# MSS_CTRL_MSS_CTRL_50D00000h register map
Vendor: Texas Instruments
Registers are 32-bit, read-write, reset values left out (the file's numbers can be read two ways) unless marked. A register's access mark holds for its fields unless they carry their own. Offsets are as the file gives them; [hi:lo] are bit positions; {n}, {i} and the like mark numbered series.

## MSS_CTRL (part 3 of 6)
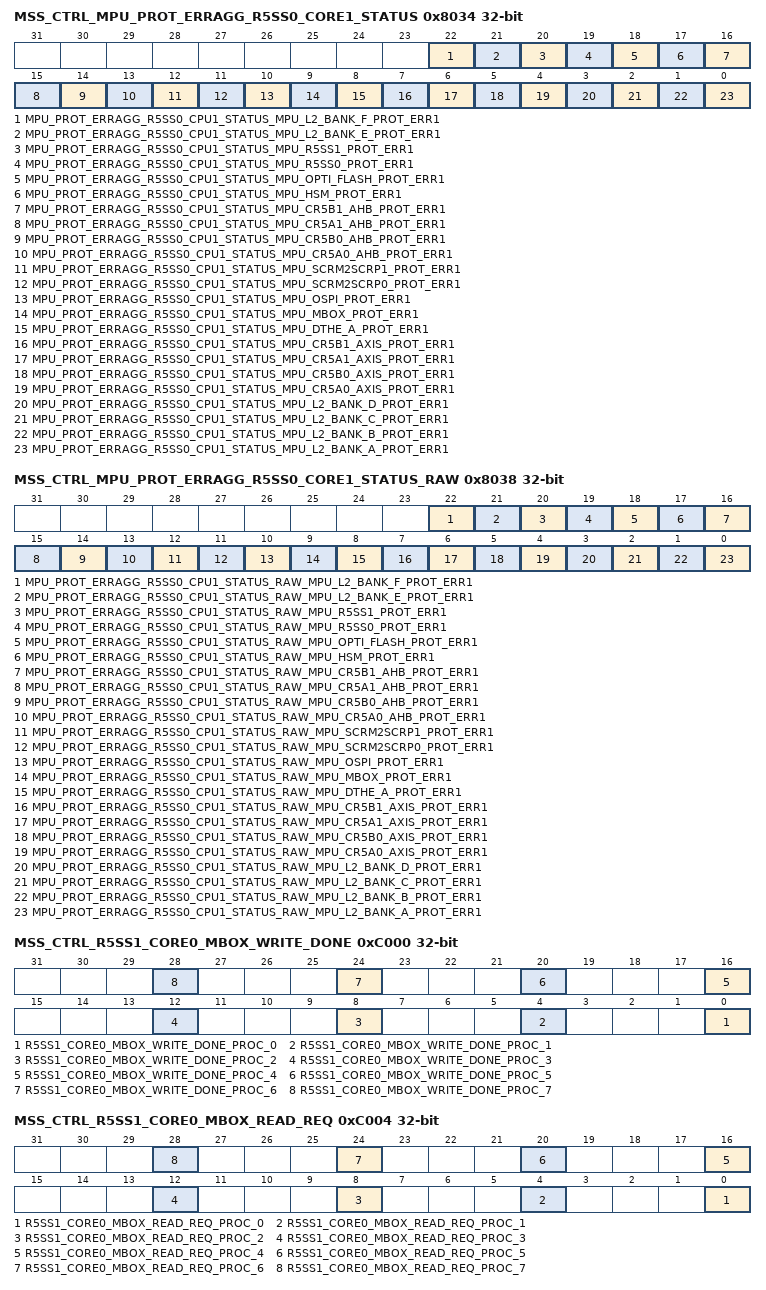
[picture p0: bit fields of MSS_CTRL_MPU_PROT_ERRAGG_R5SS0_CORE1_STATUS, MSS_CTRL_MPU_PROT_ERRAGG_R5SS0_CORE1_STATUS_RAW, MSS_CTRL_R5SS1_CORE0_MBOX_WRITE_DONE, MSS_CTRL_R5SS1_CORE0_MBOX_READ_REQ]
0x8034 MSS_CTRL_MPU_PROT_ERRAGG_R5SS0_CORE1_STATUS
  [22] MPU_PROT_ERRAGG_R5SS0_CPU1_STATUS_MPU_L2_BANK_F_PROT_ERR1 — Status of Error from MPU_PROT_INTR. Set only if Interupt is unmasked in MPU_PROT_INTR_ERRAGG_MASKWrie 0x1 to clear this Error.
  [21] MPU_PROT_ERRAGG_R5SS0_CPU1_STATUS_MPU_L2_BANK_E_PROT_ERR1 — Status of Error from MPU_PROT_INTR. Set only if Interupt is unmasked in MPU_PROT_INTR_ERRAGG_MASKWrie 0x1 to clear this Error.
  [20] MPU_PROT_ERRAGG_R5SS0_CPU1_STATUS_MPU_R5SS1_PROT_ERR1 — Status of Error from MPU_PROT_INTR. Set only if Interupt is unmasked in MPU_PROT_INTR_ERRAGG_MASKWrie 0x1 to clear this Error.
  [19] MPU_PROT_ERRAGG_R5SS0_CPU1_STATUS_MPU_R5SS0_PROT_ERR1 — Status of Error from MPU_PROT_INTR. Set only if Interupt is unmasked in MPU_PROT_INTR_ERRAGG_MASKWrie 0x1 to clear this Error.
  [18] MPU_PROT_ERRAGG_R5SS0_CPU1_STATUS_MPU_OPTI_FLASH_PROT_ERR1 — Status of Error from MPU_PROT_INTR. Set only if Interupt is unmasked in MPU_PROT_INTR_ERRAGG_MASKWrie 0x1 to clear this Error.
  [17] MPU_PROT_ERRAGG_R5SS0_CPU1_STATUS_MPU_HSM_PROT_ERR1 — Status of Error from MPU_PROT_INTR. Set only if Interupt is unmasked in MPU_PROT_INTR_ERRAGG_MASKWrie 0x1 to clear this Error.
  [16] MPU_PROT_ERRAGG_R5SS0_CPU1_STATUS_MPU_CR5B1_AHB_PROT_ERR1 — Status of Error from MPU_PROT_INTR. Set only if Interupt is unmasked in MPU_PROT_INTR_ERRAGG_MASKWrie 0x1 to clear this Error.
  [15] MPU_PROT_ERRAGG_R5SS0_CPU1_STATUS_MPU_CR5A1_AHB_PROT_ERR1 — Status of Error from MPU_PROT_INTR. Set only if Interupt is unmasked in MPU_PROT_INTR_ERRAGG_MASKWrie 0x1 to clear this Error.
  [14] MPU_PROT_ERRAGG_R5SS0_CPU1_STATUS_MPU_CR5B0_AHB_PROT_ERR1 — Status of Error from MPU_PROT_INTR. Set only if Interupt is unmasked in MPU_PROT_INTR_ERRAGG_MASKWrie 0x1 to clear this Error.
  [13] MPU_PROT_ERRAGG_R5SS0_CPU1_STATUS_MPU_CR5A0_AHB_PROT_ERR1 — Status of Error from MPU_PROT_INTR. Set only if Interupt is unmasked in MPU_PROT_INTR_ERRAGG_MASKWrie 0x1 to clear this Error.
  [12] MPU_PROT_ERRAGG_R5SS0_CPU1_STATUS_MPU_SCRM2SCRP1_PROT_ERR1 — Status of Error from MPU_PROT_INTR. Set only if Interupt is unmasked in MPU_PROT_INTR_ERRAGG_MASKWrie 0x1 to clear this Error.
  [11] MPU_PROT_ERRAGG_R5SS0_CPU1_STATUS_MPU_SCRM2SCRP0_PROT_ERR1 — Status of Error from MPU_PROT_INTR. Set only if Interupt is unmasked in MPU_PROT_INTR_ERRAGG_MASKWrie 0x1 to clear this Error.
  [10] MPU_PROT_ERRAGG_R5SS0_CPU1_STATUS_MPU_OSPI_PROT_ERR1 — Status of Error from MPU_PROT_INTR. Set only if Interupt is unmasked in MPU_PROT_INTR_ERRAGG_MASKWrie 0x1 to clear this Error.
  [9] MPU_PROT_ERRAGG_R5SS0_CPU1_STATUS_MPU_MBOX_PROT_ERR1 — Status of Error from MPU_PROT_INTR. Set only if Interupt is unmasked in MPU_PROT_INTR_ERRAGG_MASKWrie 0x1 to clear this Error.
  [8] MPU_PROT_ERRAGG_R5SS0_CPU1_STATUS_MPU_DTHE_A_PROT_ERR1 — Status of Error from MPU_PROT_INTR. Set only if Interupt is unmasked in MPU_PROT_INTR_ERRAGG_MASKWrie 0x1 to clear this Error.
  [7] MPU_PROT_ERRAGG_R5SS0_CPU1_STATUS_MPU_CR5B1_AXIS_PROT_ERR1 — Status of Error from MPU_PROT_INTR. Set only if Interupt is unmasked in MPU_PROT_INTR_ERRAGG_MASKWrie 0x1 to clear this Error.
  [6] MPU_PROT_ERRAGG_R5SS0_CPU1_STATUS_MPU_CR5A1_AXIS_PROT_ERR1 — Status of Error from MPU_PROT_INTR. Set only if Interupt is unmasked in MPU_PROT_INTR_ERRAGG_MASKWrie 0x1 to clear this Error.
  [5] MPU_PROT_ERRAGG_R5SS0_CPU1_STATUS_MPU_CR5B0_AXIS_PROT_ERR1 — Status of Error from MPU_PROT_INTR. Set only if Interupt is unmasked in MPU_PROT_INTR_ERRAGG_MASKWrie 0x1 to clear this Error.
  [4] MPU_PROT_ERRAGG_R5SS0_CPU1_STATUS_MPU_CR5A0_AXIS_PROT_ERR1 — Status of Error from MPU_PROT_INTR. Set only if Interupt is unmasked in MPU_PROT_INTR_ERRAGG_MASKWrie 0x1 to clear this Error.
  [3] MPU_PROT_ERRAGG_R5SS0_CPU1_STATUS_MPU_L2_BANK_D_PROT_ERR1 — Status of Error from MPU_PROT_INTR. Set only if Interupt is unmasked in MPU_PROT_INTR_ERRAGG_MASKWrie 0x1 to clear this Error.
  [2] MPU_PROT_ERRAGG_R5SS0_CPU1_STATUS_MPU_L2_BANK_C_PROT_ERR1 — Status of Error from MPU_PROT_INTR. Set only if Interupt is unmasked in MPU_PROT_INTR_ERRAGG_MASKWrie 0x1 to clear this Error.
  [1] MPU_PROT_ERRAGG_R5SS0_CPU1_STATUS_MPU_L2_BANK_B_PROT_ERR1 — Status of Error from MPU_PROT_INTR. Set only if Interupt is unmasked in MPU_PROT_INTR_ERRAGG_MASKWrie 0x1 to clear this Error.
  [0] MPU_PROT_ERRAGG_R5SS0_CPU1_STATUS_MPU_L2_BANK_A_PROT_ERR1 — Status of Error from MPU_PROT_INTR. Set only if Interupt is unmasked in MPU_PROT_INTR_ERRAGG_MASKWrie 0x1 to clear this Error.
0x8038 MSS_CTRL_MPU_PROT_ERRAGG_R5SS0_CORE1_STATUS_RAW
  [22] MPU_PROT_ERRAGG_R5SS0_CPU1_STATUS_RAW_MPU_L2_BANK_F_PROT_ERR1 — Raw Status of Error from MPU_PROT_INTR. Set irrespective if the Interupt is masked or unmasked in MPU_PROT_INTR_ERRAGG_MASK
  [21] MPU_PROT_ERRAGG_R5SS0_CPU1_STATUS_RAW_MPU_L2_BANK_E_PROT_ERR1 — Raw Status of Error from MPU_PROT_INTR. Set irrespective if the Interupt is masked or unmasked in MPU_PROT_INTR_ERRAGG_MASK
  [20] MPU_PROT_ERRAGG_R5SS0_CPU1_STATUS_RAW_MPU_R5SS1_PROT_ERR1 — Raw Status of Error from MPU_PROT_INTR. Set irrespective if the Interupt is masked or unmasked in MPU_PROT_INTR_ERRAGG_MASK
  [19] MPU_PROT_ERRAGG_R5SS0_CPU1_STATUS_RAW_MPU_R5SS0_PROT_ERR1 — Raw Status of Error from MPU_PROT_INTR. Set irrespective if the Interupt is masked or unmasked in MPU_PROT_INTR_ERRAGG_MASK
  [18] MPU_PROT_ERRAGG_R5SS0_CPU1_STATUS_RAW_MPU_OPTI_FLASH_PROT_ERR1 — Raw Status of Error from MPU_PROT_INTR. Set irrespective if the Interupt is masked or unmasked in MPU_PROT_INTR_ERRAGG_MASK
  [17] MPU_PROT_ERRAGG_R5SS0_CPU1_STATUS_RAW_MPU_HSM_PROT_ERR1 — Raw Status of Error from MPU_PROT_INTR. Set irrespective if the Interupt is masked or unmasked in MPU_PROT_INTR_ERRAGG_MASK
  [16] MPU_PROT_ERRAGG_R5SS0_CPU1_STATUS_RAW_MPU_CR5B1_AHB_PROT_ERR1 — Raw Status of Error from MPU_PROT_INTR. Set irrespective if the Interupt is masked or unmasked in MPU_PROT_INTR_ERRAGG_MASK
  [15] MPU_PROT_ERRAGG_R5SS0_CPU1_STATUS_RAW_MPU_CR5A1_AHB_PROT_ERR1 — Raw Status of Error from MPU_PROT_INTR. Set irrespective if the Interupt is masked or unmasked in MPU_PROT_INTR_ERRAGG_MASK
  [14] MPU_PROT_ERRAGG_R5SS0_CPU1_STATUS_RAW_MPU_CR5B0_AHB_PROT_ERR1 — Raw Status of Error from MPU_PROT_INTR. Set irrespective if the Interupt is masked or unmasked in MPU_PROT_INTR_ERRAGG_MASK
  [13] MPU_PROT_ERRAGG_R5SS0_CPU1_STATUS_RAW_MPU_CR5A0_AHB_PROT_ERR1 — Raw Status of Error from MPU_PROT_INTR. Set irrespective if the Interupt is masked or unmasked in MPU_PROT_INTR_ERRAGG_MASK
  [12] MPU_PROT_ERRAGG_R5SS0_CPU1_STATUS_RAW_MPU_SCRM2SCRP1_PROT_ERR1 — Raw Status of Error from MPU_PROT_INTR. Set irrespective if the Interupt is masked or unmasked in MPU_PROT_INTR_ERRAGG_MASK
  [11] MPU_PROT_ERRAGG_R5SS0_CPU1_STATUS_RAW_MPU_SCRM2SCRP0_PROT_ERR1 — Raw Status of Error from MPU_PROT_INTR. Set irrespective if the Interupt is masked or unmasked in MPU_PROT_INTR_ERRAGG_MASK
  [10] MPU_PROT_ERRAGG_R5SS0_CPU1_STATUS_RAW_MPU_OSPI_PROT_ERR1 — Raw Status of Error from MPU_PROT_INTR. Set irrespective if the Interupt is masked or unmasked in MPU_PROT_INTR_ERRAGG_MASK
  [9] MPU_PROT_ERRAGG_R5SS0_CPU1_STATUS_RAW_MPU_MBOX_PROT_ERR1 — Raw Status of Error from MPU_PROT_INTR. Set irrespective if the Interupt is masked or unmasked in MPU_PROT_INTR_ERRAGG_MASK
  [8] MPU_PROT_ERRAGG_R5SS0_CPU1_STATUS_RAW_MPU_DTHE_A_PROT_ERR1 — Raw Status of Error from MPU_PROT_INTR. Set irrespective if the Interupt is masked or unmasked in MPU_PROT_INTR_ERRAGG_MASK
  [7] MPU_PROT_ERRAGG_R5SS0_CPU1_STATUS_RAW_MPU_CR5B1_AXIS_PROT_ERR1 — Raw Status of Error from MPU_PROT_INTR. Set irrespective if the Interupt is masked or unmasked in MPU_PROT_INTR_ERRAGG_MASK
  [6] MPU_PROT_ERRAGG_R5SS0_CPU1_STATUS_RAW_MPU_CR5A1_AXIS_PROT_ERR1 — Raw Status of Error from MPU_PROT_INTR. Set irrespective if the Interupt is masked or unmasked in MPU_PROT_INTR_ERRAGG_MASK
  [5] MPU_PROT_ERRAGG_R5SS0_CPU1_STATUS_RAW_MPU_CR5B0_AXIS_PROT_ERR1 — Raw Status of Error from MPU_PROT_INTR. Set irrespective if the Interupt is masked or unmasked in MPU_PROT_INTR_ERRAGG_MASK
  [4] MPU_PROT_ERRAGG_R5SS0_CPU1_STATUS_RAW_MPU_CR5A0_AXIS_PROT_ERR1 — Raw Status of Error from MPU_PROT_INTR. Set irrespective if the Interupt is masked or unmasked in MPU_PROT_INTR_ERRAGG_MASK
  [3] MPU_PROT_ERRAGG_R5SS0_CPU1_STATUS_RAW_MPU_L2_BANK_D_PROT_ERR1 — Raw Status of Error from MPU_PROT_INTR. Set irrespective if the Interupt is masked or unmasked in MPU_PROT_INTR_ERRAGG_MASK
  [2] MPU_PROT_ERRAGG_R5SS0_CPU1_STATUS_RAW_MPU_L2_BANK_C_PROT_ERR1 — Raw Status of Error from MPU_PROT_INTR. Set irrespective if the Interupt is masked or unmasked in MPU_PROT_INTR_ERRAGG_MASK
  [1] MPU_PROT_ERRAGG_R5SS0_CPU1_STATUS_RAW_MPU_L2_BANK_B_PROT_ERR1 — Raw Status of Error from MPU_PROT_INTR. Set irrespective if the Interupt is masked or unmasked in MPU_PROT_INTR_ERRAGG_MASK
  [0] MPU_PROT_ERRAGG_R5SS0_CPU1_STATUS_RAW_MPU_L2_BANK_A_PROT_ERR1 — Raw Status of Error from MPU_PROT_INTR. Set irrespective if the Interupt is masked or unmasked in MPU_PROT_INTR_ERRAGG_MASK
0xC000 MSS_CTRL_R5SS1_CORE0_MBOX_WRITE_DONE
  [4n] R5SS1_CORE0_MBOX_WRITE_DONE_PROC_{n} (n=0..7) — Write pulse bit field:This register should be written once finishing Writing into the mailbox memory of processor {n}
0xC004 MSS_CTRL_R5SS1_CORE0_MBOX_READ_REQ
  [4n] R5SS1_CORE0_MBOX_READ_REQ_PROC_{n} (n=0..7) — This is request from processor {n} to mss_cr5a. Requesting it to read from mailbox.
0xC008 MSS_CTRL_R5SS1_CORE0_MBOX_READ_DONE_ACK
  [7:0] R5SS1_CORE0_MBOX_READ_DONE_ACK_PROC — Write pulse bit field:For bits 0 to7:Wrting1'b1 : Generates pulse interrupt to corresponding proc from MSS_CR5
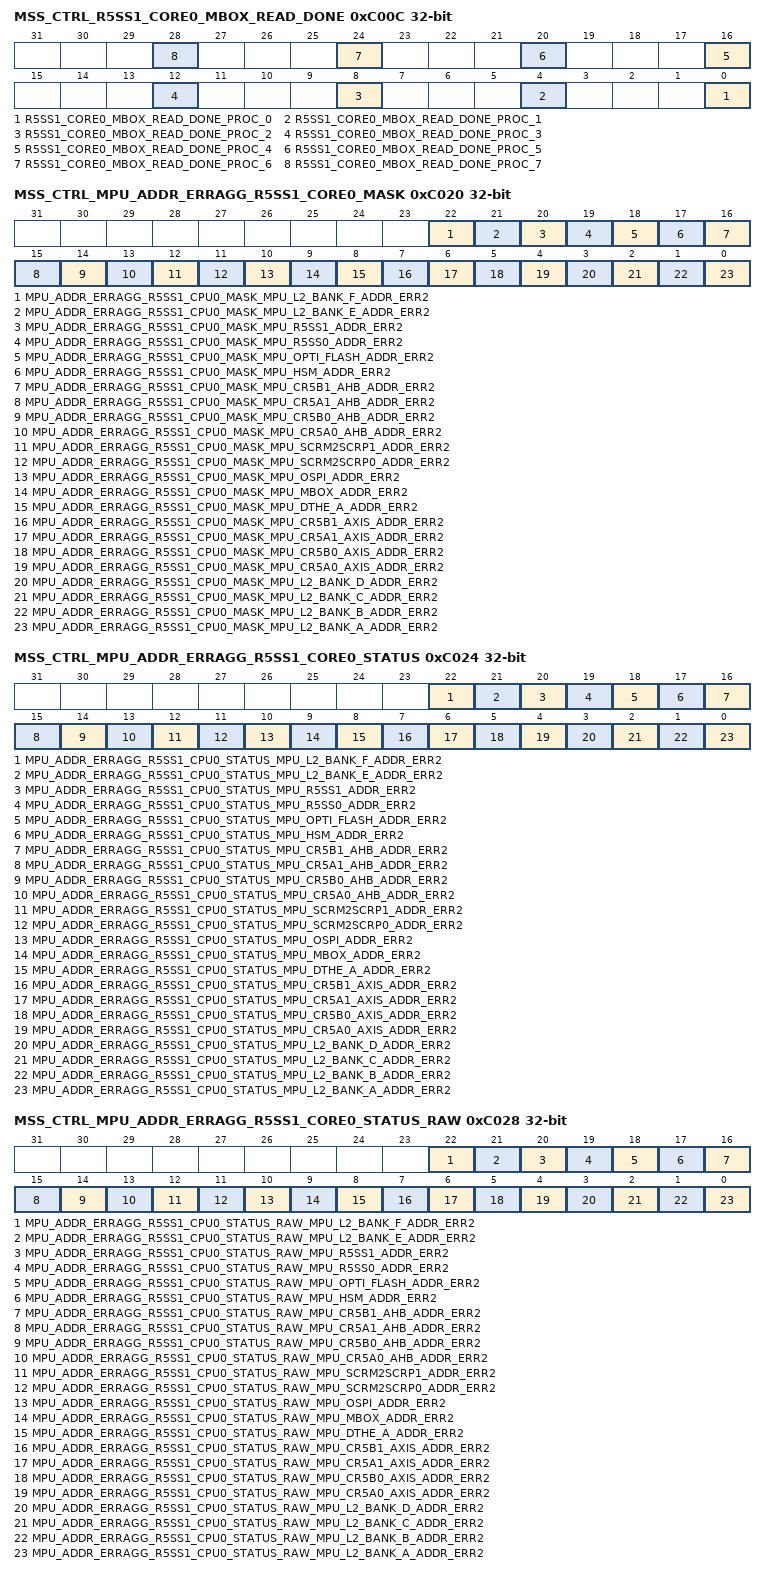
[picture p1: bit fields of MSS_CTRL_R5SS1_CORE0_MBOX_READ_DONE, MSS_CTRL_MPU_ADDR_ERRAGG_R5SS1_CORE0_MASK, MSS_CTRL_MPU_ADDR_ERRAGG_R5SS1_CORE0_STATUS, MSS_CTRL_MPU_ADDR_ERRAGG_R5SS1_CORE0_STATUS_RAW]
0xC00C MSS_CTRL_R5SS1_CORE0_MBOX_READ_DONE
  [4n] R5SS1_CORE0_MBOX_READ_DONE_PROC_{n} (n=0..7) — This register should be written once finishing Reading from proc{n}'s mailbox written by CR5A
0xC010 MSS_CTRL_R5SS1_CORE0_SW_INT
  [0] R5SS1_CORE0_SW_INT_PULSE — Write_pulse bit field:Writing 1'b1 to each bit will trigger MSS_SW_INT respectively to CR5A/B.
0xC020 MSS_CTRL_MPU_ADDR_ERRAGG_R5SS1_CORE0_MASK
  [22] MPU_ADDR_ERRAGG_R5SS1_CPU0_MASK_MPU_L2_BANK_F_ADDR_ERR2 — Mask Error from MPU_ADDR_INTR to aggregated Error MPU_ADDR_INTR_ERRAGG1'b1 : Error is Masked1'b0 : Error is Unmasked
  [21] MPU_ADDR_ERRAGG_R5SS1_CPU0_MASK_MPU_L2_BANK_E_ADDR_ERR2 — Mask Error from MPU_ADDR_INTR to aggregated Error MPU_ADDR_INTR_ERRAGG1'b1 : Error is Masked1'b0 : Error is Unmasked
  [20] MPU_ADDR_ERRAGG_R5SS1_CPU0_MASK_MPU_R5SS1_ADDR_ERR2 — Mask Error from MPU_ADDR_INTR to aggregated Error MPU_ADDR_INTR_ERRAGG1'b1 : Error is Masked1'b0 : Error is Unmasked
  [19] MPU_ADDR_ERRAGG_R5SS1_CPU0_MASK_MPU_R5SS0_ADDR_ERR2 — Mask Error from MPU_ADDR_INTR to aggregated Error MPU_ADDR_INTR_ERRAGG1'b1 : Error is Masked1'b0 : Error is Unmasked
  [18] MPU_ADDR_ERRAGG_R5SS1_CPU0_MASK_MPU_OPTI_FLASH_ADDR_ERR2 — Mask Error from MPU_ADDR_INTR to aggregated Error MPU_ADDR_INTR_ERRAGG1'b1 : Error is Masked1'b0 : Error is Unmasked
  [17] MPU_ADDR_ERRAGG_R5SS1_CPU0_MASK_MPU_HSM_ADDR_ERR2 — Mask Error from MPU_ADDR_INTR to aggregated Error MPU_ADDR_INTR_ERRAGG1'b1 : Error is Masked1'b0 : Error is Unmasked
  [16] MPU_ADDR_ERRAGG_R5SS1_CPU0_MASK_MPU_CR5B1_AHB_ADDR_ERR2 — Mask Error from MPU_ADDR_INTR to aggregated Error MPU_ADDR_INTR_ERRAGG1'b1 : Error is Masked1'b0 : Error is Unmasked
  [15] MPU_ADDR_ERRAGG_R5SS1_CPU0_MASK_MPU_CR5A1_AHB_ADDR_ERR2 — Mask Error from MPU_ADDR_INTR to aggregated Error MPU_ADDR_INTR_ERRAGG1'b1 : Error is Masked1'b0 : Error is Unmasked
  [14] MPU_ADDR_ERRAGG_R5SS1_CPU0_MASK_MPU_CR5B0_AHB_ADDR_ERR2 — Mask Error from MPU_ADDR_INTR to aggregated Error MPU_ADDR_INTR_ERRAGG1'b1 : Error is Masked1'b0 : Error is Unmasked
  [13] MPU_ADDR_ERRAGG_R5SS1_CPU0_MASK_MPU_CR5A0_AHB_ADDR_ERR2 — Mask Error from MPU_ADDR_INTR to aggregated Error MPU_ADDR_INTR_ERRAGG1'b1 : Error is Masked1'b0 : Error is Unmasked
  [12] MPU_ADDR_ERRAGG_R5SS1_CPU0_MASK_MPU_SCRM2SCRP1_ADDR_ERR2 — Mask Error from MPU_ADDR_INTR to aggregated Error MPU_ADDR_INTR_ERRAGG1'b1 : Error is Masked1'b0 : Error is Unmasked
  [11] MPU_ADDR_ERRAGG_R5SS1_CPU0_MASK_MPU_SCRM2SCRP0_ADDR_ERR2 — Mask Error from MPU_ADDR_INTR to aggregated Error MPU_ADDR_INTR_ERRAGG1'b1 : Error is Masked1'b0 : Error is Unmasked
  [10] MPU_ADDR_ERRAGG_R5SS1_CPU0_MASK_MPU_OSPI_ADDR_ERR2 — Mask Error from MPU_ADDR_INTR to aggregated Error MPU_ADDR_INTR_ERRAGG1'b1 : Error is Masked1'b0 : Error is Unmasked
  [9] MPU_ADDR_ERRAGG_R5SS1_CPU0_MASK_MPU_MBOX_ADDR_ERR2 — Mask Error from MPU_ADDR_INTR to aggregated Error MPU_ADDR_INTR_ERRAGG1'b1 : Error is Masked1'b0 : Error is Unmasked
  [8] MPU_ADDR_ERRAGG_R5SS1_CPU0_MASK_MPU_DTHE_A_ADDR_ERR2 — Mask Error from MPU_ADDR_INTR to aggregated Error MPU_ADDR_INTR_ERRAGG1'b1 : Error is Masked1'b0 : Error is Unmasked
  [7] MPU_ADDR_ERRAGG_R5SS1_CPU0_MASK_MPU_CR5B1_AXIS_ADDR_ERR2 — Mask Error from MPU_ADDR_INTR to aggregated Error MPU_ADDR_INTR_ERRAGG1'b1 : Error is Masked1'b0 : Error is Unmasked
  [6] MPU_ADDR_ERRAGG_R5SS1_CPU0_MASK_MPU_CR5A1_AXIS_ADDR_ERR2 — Mask Error from MPU_ADDR_INTR to aggregated Error MPU_ADDR_INTR_ERRAGG1'b1 : Error is Masked1'b0 : Error is Unmasked
  [5] MPU_ADDR_ERRAGG_R5SS1_CPU0_MASK_MPU_CR5B0_AXIS_ADDR_ERR2 — Mask Error from MPU_ADDR_INTR to aggregated Error MPU_ADDR_INTR_ERRAGG1'b1 : Error is Masked1'b0 : Error is Unmasked
  [4] MPU_ADDR_ERRAGG_R5SS1_CPU0_MASK_MPU_CR5A0_AXIS_ADDR_ERR2 — Mask Error from MPU_ADDR_INTR to aggregated Error MPU_ADDR_INTR_ERRAGG1'b1 : Error is Masked1'b0 : Error is Unmasked
  [3] MPU_ADDR_ERRAGG_R5SS1_CPU0_MASK_MPU_L2_BANK_D_ADDR_ERR2 — Mask Error from MPU_ADDR_INTR to aggregated Error MPU_ADDR_INTR_ERRAGG1'b1 : Error is Masked1'b0 : Error is Unmasked
  [2] MPU_ADDR_ERRAGG_R5SS1_CPU0_MASK_MPU_L2_BANK_C_ADDR_ERR2 — Mask Error from MPU_ADDR_INTR to aggregated Error MPU_ADDR_INTR_ERRAGG1'b1 : Error is Masked1'b0 : Error is Unmasked
  [1] MPU_ADDR_ERRAGG_R5SS1_CPU0_MASK_MPU_L2_BANK_B_ADDR_ERR2 — Mask Error from MPU_ADDR_INTR to aggregated Error MPU_ADDR_INTR_ERRAGG1'b1 : Error is Masked1'b0 : Error is Unmasked
  [0] MPU_ADDR_ERRAGG_R5SS1_CPU0_MASK_MPU_L2_BANK_A_ADDR_ERR2 — Mask Error from MPU_ADDR_INTR to aggregated Error MPU_ADDR_INTR_ERRAGG1'b1 : Error is Masked1'b0 : Error is Unmasked
0xC024 MSS_CTRL_MPU_ADDR_ERRAGG_R5SS1_CORE0_STATUS
  [22] MPU_ADDR_ERRAGG_R5SS1_CPU0_STATUS_MPU_L2_BANK_F_ADDR_ERR2 — Status of Error from MPU_ADDR_INTR. Set only if Interupt is unmasked in MPU_ADDR_INTR_ERRAGG_MASKWrie 0x1 to clear this Error.
  [21] MPU_ADDR_ERRAGG_R5SS1_CPU0_STATUS_MPU_L2_BANK_E_ADDR_ERR2 — Status of Error from MPU_ADDR_INTR. Set only if Interupt is unmasked in MPU_ADDR_INTR_ERRAGG_MASKWrie 0x1 to clear this Error.
  [20] MPU_ADDR_ERRAGG_R5SS1_CPU0_STATUS_MPU_R5SS1_ADDR_ERR2 — Status of Error from MPU_ADDR_INTR. Set only if Interupt is unmasked in MPU_ADDR_INTR_ERRAGG_MASKWrie 0x1 to clear this Error.
  [19] MPU_ADDR_ERRAGG_R5SS1_CPU0_STATUS_MPU_R5SS0_ADDR_ERR2 — Status of Error from MPU_ADDR_INTR. Set only if Interupt is unmasked in MPU_ADDR_INTR_ERRAGG_MASKWrie 0x1 to clear this Error.
  [18] MPU_ADDR_ERRAGG_R5SS1_CPU0_STATUS_MPU_OPTI_FLASH_ADDR_ERR2 — Status of Error from MPU_ADDR_INTR. Set only if Interupt is unmasked in MPU_ADDR_INTR_ERRAGG_MASKWrie 0x1 to clear this Error.
  [17] MPU_ADDR_ERRAGG_R5SS1_CPU0_STATUS_MPU_HSM_ADDR_ERR2 — Status of Error from MPU_ADDR_INTR. Set only if Interupt is unmasked in MPU_ADDR_INTR_ERRAGG_MASKWrie 0x1 to clear this Error.
  [16] MPU_ADDR_ERRAGG_R5SS1_CPU0_STATUS_MPU_CR5B1_AHB_ADDR_ERR2 — Status of Error from MPU_ADDR_INTR. Set only if Interupt is unmasked in MPU_ADDR_INTR_ERRAGG_MASKWrie 0x1 to clear this Error.
  [15] MPU_ADDR_ERRAGG_R5SS1_CPU0_STATUS_MPU_CR5A1_AHB_ADDR_ERR2 — Status of Error from MPU_ADDR_INTR. Set only if Interupt is unmasked in MPU_ADDR_INTR_ERRAGG_MASKWrie 0x1 to clear this Error.
  [14] MPU_ADDR_ERRAGG_R5SS1_CPU0_STATUS_MPU_CR5B0_AHB_ADDR_ERR2 — Status of Error from MPU_ADDR_INTR. Set only if Interupt is unmasked in MPU_ADDR_INTR_ERRAGG_MASKWrie 0x1 to clear this Error.
  [13] MPU_ADDR_ERRAGG_R5SS1_CPU0_STATUS_MPU_CR5A0_AHB_ADDR_ERR2 — Status of Error from MPU_ADDR_INTR. Set only if Interupt is unmasked in MPU_ADDR_INTR_ERRAGG_MASKWrie 0x1 to clear this Error.
  [12] MPU_ADDR_ERRAGG_R5SS1_CPU0_STATUS_MPU_SCRM2SCRP1_ADDR_ERR2 — Status of Error from MPU_ADDR_INTR. Set only if Interupt is unmasked in MPU_ADDR_INTR_ERRAGG_MASKWrie 0x1 to clear this Error.
  [11] MPU_ADDR_ERRAGG_R5SS1_CPU0_STATUS_MPU_SCRM2SCRP0_ADDR_ERR2 — Status of Error from MPU_ADDR_INTR. Set only if Interupt is unmasked in MPU_ADDR_INTR_ERRAGG_MASKWrie 0x1 to clear this Error.
  [10] MPU_ADDR_ERRAGG_R5SS1_CPU0_STATUS_MPU_OSPI_ADDR_ERR2 — Status of Error from MPU_ADDR_INTR. Set only if Interupt is unmasked in MPU_ADDR_INTR_ERRAGG_MASKWrie 0x1 to clear this Error.
  [9] MPU_ADDR_ERRAGG_R5SS1_CPU0_STATUS_MPU_MBOX_ADDR_ERR2 — Status of Error from MPU_ADDR_INTR. Set only if Interupt is unmasked in MPU_ADDR_INTR_ERRAGG_MASKWrie 0x1 to clear this Error.
  [8] MPU_ADDR_ERRAGG_R5SS1_CPU0_STATUS_MPU_DTHE_A_ADDR_ERR2 — Status of Error from MPU_ADDR_INTR. Set only if Interupt is unmasked in MPU_ADDR_INTR_ERRAGG_MASKWrie 0x1 to clear this Error.
  [7] MPU_ADDR_ERRAGG_R5SS1_CPU0_STATUS_MPU_CR5B1_AXIS_ADDR_ERR2 — Status of Error from MPU_ADDR_INTR. Set only if Interupt is unmasked in MPU_ADDR_INTR_ERRAGG_MASKWrie 0x1 to clear this Error.
  [6] MPU_ADDR_ERRAGG_R5SS1_CPU0_STATUS_MPU_CR5A1_AXIS_ADDR_ERR2 — Status of Error from MPU_ADDR_INTR. Set only if Interupt is unmasked in MPU_ADDR_INTR_ERRAGG_MASKWrie 0x1 to clear this Error.
  [5] MPU_ADDR_ERRAGG_R5SS1_CPU0_STATUS_MPU_CR5B0_AXIS_ADDR_ERR2 — Status of Error from MPU_ADDR_INTR. Set only if Interupt is unmasked in MPU_ADDR_INTR_ERRAGG_MASKWrie 0x1 to clear this Error.
  [4] MPU_ADDR_ERRAGG_R5SS1_CPU0_STATUS_MPU_CR5A0_AXIS_ADDR_ERR2 — Status of Error from MPU_ADDR_INTR. Set only if Interupt is unmasked in MPU_ADDR_INTR_ERRAGG_MASKWrie 0x1 to clear this Error.
  [3] MPU_ADDR_ERRAGG_R5SS1_CPU0_STATUS_MPU_L2_BANK_D_ADDR_ERR2 — Status of Error from MPU_ADDR_INTR. Set only if Interupt is unmasked in MPU_ADDR_INTR_ERRAGG_MASKWrie 0x1 to clear this Error.
  [2] MPU_ADDR_ERRAGG_R5SS1_CPU0_STATUS_MPU_L2_BANK_C_ADDR_ERR2 — Status of Error from MPU_ADDR_INTR. Set only if Interupt is unmasked in MPU_ADDR_INTR_ERRAGG_MASKWrie 0x1 to clear this Error.
  [1] MPU_ADDR_ERRAGG_R5SS1_CPU0_STATUS_MPU_L2_BANK_B_ADDR_ERR2 — Status of Error from MPU_ADDR_INTR. Set only if Interupt is unmasked in MPU_ADDR_INTR_ERRAGG_MASKWrie 0x1 to clear this Error.
  [0] MPU_ADDR_ERRAGG_R5SS1_CPU0_STATUS_MPU_L2_BANK_A_ADDR_ERR2 — Status of Error from MPU_ADDR_INTR. Set only if Interupt is unmasked in MPU_ADDR_INTR_ERRAGG_MASKWrie 0x1 to clear this Error.
0xC028 MSS_CTRL_MPU_ADDR_ERRAGG_R5SS1_CORE0_STATUS_RAW
  [22] MPU_ADDR_ERRAGG_R5SS1_CPU0_STATUS_RAW_MPU_L2_BANK_F_ADDR_ERR2 — Raw Status of Error from MPU_ADDR_INTR. Set irrespective if the Interupt is masked or unmasked in MPU_ADDR_INTR_ERRAGG_MASK
  [21] MPU_ADDR_ERRAGG_R5SS1_CPU0_STATUS_RAW_MPU_L2_BANK_E_ADDR_ERR2 — Raw Status of Error from MPU_ADDR_INTR. Set irrespective if the Interupt is masked or unmasked in MPU_ADDR_INTR_ERRAGG_MASK
  [20] MPU_ADDR_ERRAGG_R5SS1_CPU0_STATUS_RAW_MPU_R5SS1_ADDR_ERR2 — Raw Status of Error from MPU_ADDR_INTR. Set irrespective if the Interupt is masked or unmasked in MPU_ADDR_INTR_ERRAGG_MASK
  [19] MPU_ADDR_ERRAGG_R5SS1_CPU0_STATUS_RAW_MPU_R5SS0_ADDR_ERR2 — Raw Status of Error from MPU_ADDR_INTR. Set irrespective if the Interupt is masked or unmasked in MPU_ADDR_INTR_ERRAGG_MASK
  [18] MPU_ADDR_ERRAGG_R5SS1_CPU0_STATUS_RAW_MPU_OPTI_FLASH_ADDR_ERR2 — Raw Status of Error from MPU_ADDR_INTR. Set irrespective if the Interupt is masked or unmasked in MPU_ADDR_INTR_ERRAGG_MASK
  [17] MPU_ADDR_ERRAGG_R5SS1_CPU0_STATUS_RAW_MPU_HSM_ADDR_ERR2 — Raw Status of Error from MPU_ADDR_INTR. Set irrespective if the Interupt is masked or unmasked in MPU_ADDR_INTR_ERRAGG_MASK
  [16] MPU_ADDR_ERRAGG_R5SS1_CPU0_STATUS_RAW_MPU_CR5B1_AHB_ADDR_ERR2 — Raw Status of Error from MPU_ADDR_INTR. Set irrespective if the Interupt is masked or unmasked in MPU_ADDR_INTR_ERRAGG_MASK
  [15] MPU_ADDR_ERRAGG_R5SS1_CPU0_STATUS_RAW_MPU_CR5A1_AHB_ADDR_ERR2 — Raw Status of Error from MPU_ADDR_INTR. Set irrespective if the Interupt is masked or unmasked in MPU_ADDR_INTR_ERRAGG_MASK
  [14] MPU_ADDR_ERRAGG_R5SS1_CPU0_STATUS_RAW_MPU_CR5B0_AHB_ADDR_ERR2 — Raw Status of Error from MPU_ADDR_INTR. Set irrespective if the Interupt is masked or unmasked in MPU_ADDR_INTR_ERRAGG_MASK
  [13] MPU_ADDR_ERRAGG_R5SS1_CPU0_STATUS_RAW_MPU_CR5A0_AHB_ADDR_ERR2 — Raw Status of Error from MPU_ADDR_INTR. Set irrespective if the Interupt is masked or unmasked in MPU_ADDR_INTR_ERRAGG_MASK
  [12] MPU_ADDR_ERRAGG_R5SS1_CPU0_STATUS_RAW_MPU_SCRM2SCRP1_ADDR_ERR2 — Raw Status of Error from MPU_ADDR_INTR. Set irrespective if the Interupt is masked or unmasked in MPU_ADDR_INTR_ERRAGG_MASK
  [11] MPU_ADDR_ERRAGG_R5SS1_CPU0_STATUS_RAW_MPU_SCRM2SCRP0_ADDR_ERR2 — Raw Status of Error from MPU_ADDR_INTR. Set irrespective if the Interupt is masked or unmasked in MPU_ADDR_INTR_ERRAGG_MASK
  [10] MPU_ADDR_ERRAGG_R5SS1_CPU0_STATUS_RAW_MPU_OSPI_ADDR_ERR2 — Raw Status of Error from MPU_ADDR_INTR. Set irrespective if the Interupt is masked or unmasked in MPU_ADDR_INTR_ERRAGG_MASK
  [9] MPU_ADDR_ERRAGG_R5SS1_CPU0_STATUS_RAW_MPU_MBOX_ADDR_ERR2 — Raw Status of Error from MPU_ADDR_INTR. Set irrespective if the Interupt is masked or unmasked in MPU_ADDR_INTR_ERRAGG_MASK
  [8] MPU_ADDR_ERRAGG_R5SS1_CPU0_STATUS_RAW_MPU_DTHE_A_ADDR_ERR2 — Raw Status of Error from MPU_ADDR_INTR. Set irrespective if the Interupt is masked or unmasked in MPU_ADDR_INTR_ERRAGG_MASK
  [7] MPU_ADDR_ERRAGG_R5SS1_CPU0_STATUS_RAW_MPU_CR5B1_AXIS_ADDR_ERR2 — Raw Status of Error from MPU_ADDR_INTR. Set irrespective if the Interupt is masked or unmasked in MPU_ADDR_INTR_ERRAGG_MASK
  [6] MPU_ADDR_ERRAGG_R5SS1_CPU0_STATUS_RAW_MPU_CR5A1_AXIS_ADDR_ERR2 — Raw Status of Error from MPU_ADDR_INTR. Set irrespective if the Interupt is masked or unmasked in MPU_ADDR_INTR_ERRAGG_MASK
  [5] MPU_ADDR_ERRAGG_R5SS1_CPU0_STATUS_RAW_MPU_CR5B0_AXIS_ADDR_ERR2 — Raw Status of Error from MPU_ADDR_INTR. Set irrespective if the Interupt is masked or unmasked in MPU_ADDR_INTR_ERRAGG_MASK
  [4] MPU_ADDR_ERRAGG_R5SS1_CPU0_STATUS_RAW_MPU_CR5A0_AXIS_ADDR_ERR2 — Raw Status of Error from MPU_ADDR_INTR. Set irrespective if the Interupt is masked or unmasked in MPU_ADDR_INTR_ERRAGG_MASK
  [3] MPU_ADDR_ERRAGG_R5SS1_CPU0_STATUS_RAW_MPU_L2_BANK_D_ADDR_ERR2 — Raw Status of Error from MPU_ADDR_INTR. Set irrespective if the Interupt is masked or unmasked in MPU_ADDR_INTR_ERRAGG_MASK
  [2] MPU_ADDR_ERRAGG_R5SS1_CPU0_STATUS_RAW_MPU_L2_BANK_C_ADDR_ERR2 — Raw Status of Error from MPU_ADDR_INTR. Set irrespective if the Interupt is masked or unmasked in MPU_ADDR_INTR_ERRAGG_MASK
  [1] MPU_ADDR_ERRAGG_R5SS1_CPU0_STATUS_RAW_MPU_L2_BANK_B_ADDR_ERR2 — Raw Status of Error from MPU_ADDR_INTR. Set irrespective if the Interupt is masked or unmasked in MPU_ADDR_INTR_ERRAGG_MASK
  [0] MPU_ADDR_ERRAGG_R5SS1_CPU0_STATUS_RAW_MPU_L2_BANK_A_ADDR_ERR2 — Raw Status of Error from MPU_ADDR_INTR. Set irrespective if the Interupt is masked or unmasked in MPU_ADDR_INTR_ERRAGG_MASK
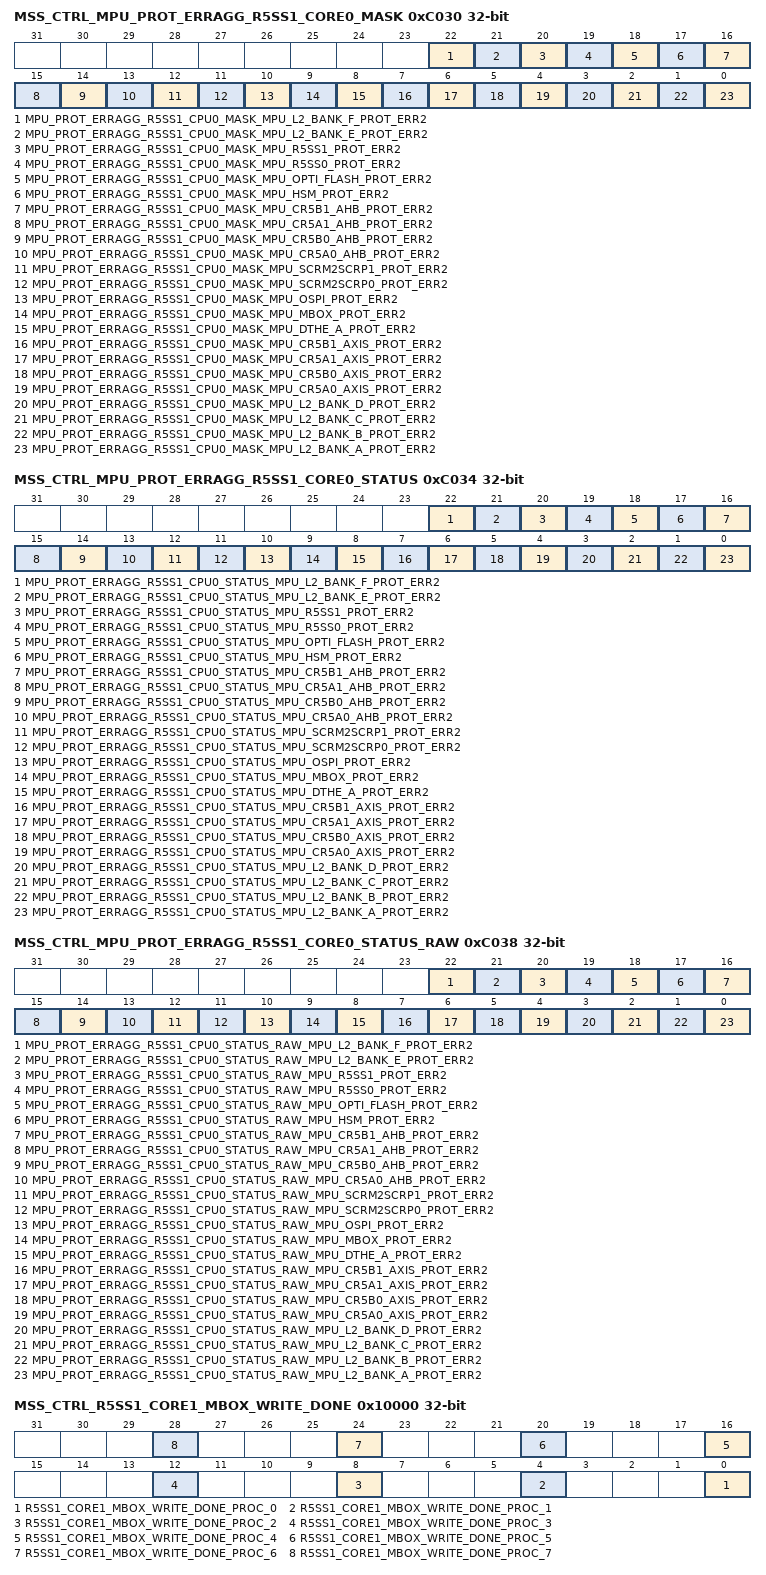
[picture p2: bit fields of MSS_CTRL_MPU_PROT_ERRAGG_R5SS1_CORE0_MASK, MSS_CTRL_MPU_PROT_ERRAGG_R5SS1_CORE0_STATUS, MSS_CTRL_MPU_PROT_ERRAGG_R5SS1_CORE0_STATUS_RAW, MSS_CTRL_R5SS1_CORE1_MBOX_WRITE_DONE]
0xC030 MSS_CTRL_MPU_PROT_ERRAGG_R5SS1_CORE0_MASK
  [22] MPU_PROT_ERRAGG_R5SS1_CPU0_MASK_MPU_L2_BANK_F_PROT_ERR2 — Mask Error from MPU_PROT_INTR to aggregated Error MPU_PROT_INTR_ERRAGG1'b1 : Error is Masked1'b0 : Error is Unmasked
  [21] MPU_PROT_ERRAGG_R5SS1_CPU0_MASK_MPU_L2_BANK_E_PROT_ERR2 — Mask Error from MPU_PROT_INTR to aggregated Error MPU_PROT_INTR_ERRAGG1'b1 : Error is Masked1'b0 : Error is Unmasked
  [20] MPU_PROT_ERRAGG_R5SS1_CPU0_MASK_MPU_R5SS1_PROT_ERR2 — Mask Error from MPU_PROT_INTR to aggregated Error MPU_PROT_INTR_ERRAGG1'b1 : Error is Masked1'b0 : Error is Unmasked
  [19] MPU_PROT_ERRAGG_R5SS1_CPU0_MASK_MPU_R5SS0_PROT_ERR2 — Mask Error from MPU_PROT_INTR to aggregated Error MPU_PROT_INTR_ERRAGG1'b1 : Error is Masked1'b0 : Error is Unmasked
  [18] MPU_PROT_ERRAGG_R5SS1_CPU0_MASK_MPU_OPTI_FLASH_PROT_ERR2 — Mask Error from MPU_PROT_INTR to aggregated Error MPU_PROT_INTR_ERRAGG1'b1 : Error is Masked1'b0 : Error is Unmasked
  [17] MPU_PROT_ERRAGG_R5SS1_CPU0_MASK_MPU_HSM_PROT_ERR2 — Mask Error from MPU_PROT_INTR to aggregated Error MPU_PROT_INTR_ERRAGG1'b1 : Error is Masked1'b0 : Error is Unmasked
  [16] MPU_PROT_ERRAGG_R5SS1_CPU0_MASK_MPU_CR5B1_AHB_PROT_ERR2 — Mask Error from MPU_PROT_INTR to aggregated Error MPU_PROT_INTR_ERRAGG1'b1 : Error is Masked1'b0 : Error is Unmasked
  [15] MPU_PROT_ERRAGG_R5SS1_CPU0_MASK_MPU_CR5A1_AHB_PROT_ERR2 — Mask Error from MPU_PROT_INTR to aggregated Error MPU_PROT_INTR_ERRAGG1'b1 : Error is Masked1'b0 : Error is Unmasked
  [14] MPU_PROT_ERRAGG_R5SS1_CPU0_MASK_MPU_CR5B0_AHB_PROT_ERR2 — Mask Error from MPU_PROT_INTR to aggregated Error MPU_PROT_INTR_ERRAGG1'b1 : Error is Masked1'b0 : Error is Unmasked
  [13] MPU_PROT_ERRAGG_R5SS1_CPU0_MASK_MPU_CR5A0_AHB_PROT_ERR2 — Mask Error from MPU_PROT_INTR to aggregated Error MPU_PROT_INTR_ERRAGG1'b1 : Error is Masked1'b0 : Error is Unmasked
  [12] MPU_PROT_ERRAGG_R5SS1_CPU0_MASK_MPU_SCRM2SCRP1_PROT_ERR2 — Mask Error from MPU_PROT_INTR to aggregated Error MPU_PROT_INTR_ERRAGG1'b1 : Error is Masked1'b0 : Error is Unmasked
  [11] MPU_PROT_ERRAGG_R5SS1_CPU0_MASK_MPU_SCRM2SCRP0_PROT_ERR2 — Mask Error from MPU_PROT_INTR to aggregated Error MPU_PROT_INTR_ERRAGG1'b1 : Error is Masked1'b0 : Error is Unmasked
  [10] MPU_PROT_ERRAGG_R5SS1_CPU0_MASK_MPU_OSPI_PROT_ERR2 — Mask Error from MPU_PROT_INTR to aggregated Error MPU_PROT_INTR_ERRAGG1'b1 : Error is Masked1'b0 : Error is Unmasked
  [9] MPU_PROT_ERRAGG_R5SS1_CPU0_MASK_MPU_MBOX_PROT_ERR2 — Mask Error from MPU_PROT_INTR to aggregated Error MPU_PROT_INTR_ERRAGG1'b1 : Error is Masked1'b0 : Error is Unmasked
  [8] MPU_PROT_ERRAGG_R5SS1_CPU0_MASK_MPU_DTHE_A_PROT_ERR2 — Mask Error from MPU_PROT_INTR to aggregated Error MPU_PROT_INTR_ERRAGG1'b1 : Error is Masked1'b0 : Error is Unmasked
  [7] MPU_PROT_ERRAGG_R5SS1_CPU0_MASK_MPU_CR5B1_AXIS_PROT_ERR2 — Mask Error from MPU_PROT_INTR to aggregated Error MPU_PROT_INTR_ERRAGG1'b1 : Error is Masked1'b0 : Error is Unmasked
  [6] MPU_PROT_ERRAGG_R5SS1_CPU0_MASK_MPU_CR5A1_AXIS_PROT_ERR2 — Mask Error from MPU_PROT_INTR to aggregated Error MPU_PROT_INTR_ERRAGG1'b1 : Error is Masked1'b0 : Error is Unmasked
  [5] MPU_PROT_ERRAGG_R5SS1_CPU0_MASK_MPU_CR5B0_AXIS_PROT_ERR2 — Mask Error from MPU_PROT_INTR to aggregated Error MPU_PROT_INTR_ERRAGG1'b1 : Error is Masked1'b0 : Error is Unmasked
  [4] MPU_PROT_ERRAGG_R5SS1_CPU0_MASK_MPU_CR5A0_AXIS_PROT_ERR2 — Mask Error from MPU_PROT_INTR to aggregated Error MPU_PROT_INTR_ERRAGG1'b1 : Error is Masked1'b0 : Error is Unmasked
  [3] MPU_PROT_ERRAGG_R5SS1_CPU0_MASK_MPU_L2_BANK_D_PROT_ERR2 — Mask Error from MPU_PROT_INTR to aggregated Error MPU_PROT_INTR_ERRAGG1'b1 : Error is Masked1'b0 : Error is Unmasked
  [2] MPU_PROT_ERRAGG_R5SS1_CPU0_MASK_MPU_L2_BANK_C_PROT_ERR2 — Mask Error from MPU_PROT_INTR to aggregated Error MPU_PROT_INTR_ERRAGG1'b1 : Error is Masked1'b0 : Error is Unmasked
  [1] MPU_PROT_ERRAGG_R5SS1_CPU0_MASK_MPU_L2_BANK_B_PROT_ERR2 — Mask Error from MPU_PROT_INTR to aggregated Error MPU_PROT_INTR_ERRAGG1'b1 : Error is Masked1'b0 : Error is Unmasked
  [0] MPU_PROT_ERRAGG_R5SS1_CPU0_MASK_MPU_L2_BANK_A_PROT_ERR2 — Mask Error from MPU_PROT_INTR to aggregated Error MPU_PROT_INTR_ERRAGG1'b1 : Error is Masked1'b0 : Error is Unmasked
0xC034 MSS_CTRL_MPU_PROT_ERRAGG_R5SS1_CORE0_STATUS
  [22] MPU_PROT_ERRAGG_R5SS1_CPU0_STATUS_MPU_L2_BANK_F_PROT_ERR2 — Status of Error from MPU_PROT_INTR. Set only if Interupt is unmasked in MPU_PROT_INTR_ERRAGG_MASKWrie 0x1 to clear this Error.
  [21] MPU_PROT_ERRAGG_R5SS1_CPU0_STATUS_MPU_L2_BANK_E_PROT_ERR2 — Status of Error from MPU_PROT_INTR. Set only if Interupt is unmasked in MPU_PROT_INTR_ERRAGG_MASKWrie 0x1 to clear this Error.
  [20] MPU_PROT_ERRAGG_R5SS1_CPU0_STATUS_MPU_R5SS1_PROT_ERR2 — Status of Error from MPU_PROT_INTR. Set only if Interupt is unmasked in MPU_PROT_INTR_ERRAGG_MASKWrie 0x1 to clear this Error.
  [19] MPU_PROT_ERRAGG_R5SS1_CPU0_STATUS_MPU_R5SS0_PROT_ERR2 — Status of Error from MPU_PROT_INTR. Set only if Interupt is unmasked in MPU_PROT_INTR_ERRAGG_MASKWrie 0x1 to clear this Error.
  [18] MPU_PROT_ERRAGG_R5SS1_CPU0_STATUS_MPU_OPTI_FLASH_PROT_ERR2 — Status of Error from MPU_PROT_INTR. Set only if Interupt is unmasked in MPU_PROT_INTR_ERRAGG_MASKWrie 0x1 to clear this Error.
  [17] MPU_PROT_ERRAGG_R5SS1_CPU0_STATUS_MPU_HSM_PROT_ERR2 — Status of Error from MPU_PROT_INTR. Set only if Interupt is unmasked in MPU_PROT_INTR_ERRAGG_MASKWrie 0x1 to clear this Error.
  [16] MPU_PROT_ERRAGG_R5SS1_CPU0_STATUS_MPU_CR5B1_AHB_PROT_ERR2 — Status of Error from MPU_PROT_INTR. Set only if Interupt is unmasked in MPU_PROT_INTR_ERRAGG_MASKWrie 0x1 to clear this Error.
  [15] MPU_PROT_ERRAGG_R5SS1_CPU0_STATUS_MPU_CR5A1_AHB_PROT_ERR2 — Status of Error from MPU_PROT_INTR. Set only if Interupt is unmasked in MPU_PROT_INTR_ERRAGG_MASKWrie 0x1 to clear this Error.
  [14] MPU_PROT_ERRAGG_R5SS1_CPU0_STATUS_MPU_CR5B0_AHB_PROT_ERR2 — Status of Error from MPU_PROT_INTR. Set only if Interupt is unmasked in MPU_PROT_INTR_ERRAGG_MASKWrie 0x1 to clear this Error.
  [13] MPU_PROT_ERRAGG_R5SS1_CPU0_STATUS_MPU_CR5A0_AHB_PROT_ERR2 — Status of Error from MPU_PROT_INTR. Set only if Interupt is unmasked in MPU_PROT_INTR_ERRAGG_MASKWrie 0x1 to clear this Error.
  [12] MPU_PROT_ERRAGG_R5SS1_CPU0_STATUS_MPU_SCRM2SCRP1_PROT_ERR2 — Status of Error from MPU_PROT_INTR. Set only if Interupt is unmasked in MPU_PROT_INTR_ERRAGG_MASKWrie 0x1 to clear this Error.
  [11] MPU_PROT_ERRAGG_R5SS1_CPU0_STATUS_MPU_SCRM2SCRP0_PROT_ERR2 — Status of Error from MPU_PROT_INTR. Set only if Interupt is unmasked in MPU_PROT_INTR_ERRAGG_MASKWrie 0x1 to clear this Error.
  [10] MPU_PROT_ERRAGG_R5SS1_CPU0_STATUS_MPU_OSPI_PROT_ERR2 — Status of Error from MPU_PROT_INTR. Set only if Interupt is unmasked in MPU_PROT_INTR_ERRAGG_MASKWrie 0x1 to clear this Error.
  [9] MPU_PROT_ERRAGG_R5SS1_CPU0_STATUS_MPU_MBOX_PROT_ERR2 — Status of Error from MPU_PROT_INTR. Set only if Interupt is unmasked in MPU_PROT_INTR_ERRAGG_MASKWrie 0x1 to clear this Error.
  [8] MPU_PROT_ERRAGG_R5SS1_CPU0_STATUS_MPU_DTHE_A_PROT_ERR2 — Status of Error from MPU_PROT_INTR. Set only if Interupt is unmasked in MPU_PROT_INTR_ERRAGG_MASKWrie 0x1 to clear this Error.
  [7] MPU_PROT_ERRAGG_R5SS1_CPU0_STATUS_MPU_CR5B1_AXIS_PROT_ERR2 — Status of Error from MPU_PROT_INTR. Set only if Interupt is unmasked in MPU_PROT_INTR_ERRAGG_MASKWrie 0x1 to clear this Error.
  [6] MPU_PROT_ERRAGG_R5SS1_CPU0_STATUS_MPU_CR5A1_AXIS_PROT_ERR2 — Status of Error from MPU_PROT_INTR. Set only if Interupt is unmasked in MPU_PROT_INTR_ERRAGG_MASKWrie 0x1 to clear this Error.
  [5] MPU_PROT_ERRAGG_R5SS1_CPU0_STATUS_MPU_CR5B0_AXIS_PROT_ERR2 — Status of Error from MPU_PROT_INTR. Set only if Interupt is unmasked in MPU_PROT_INTR_ERRAGG_MASKWrie 0x1 to clear this Error.
  [4] MPU_PROT_ERRAGG_R5SS1_CPU0_STATUS_MPU_CR5A0_AXIS_PROT_ERR2 — Status of Error from MPU_PROT_INTR. Set only if Interupt is unmasked in MPU_PROT_INTR_ERRAGG_MASKWrie 0x1 to clear this Error.
  [3] MPU_PROT_ERRAGG_R5SS1_CPU0_STATUS_MPU_L2_BANK_D_PROT_ERR2 — Status of Error from MPU_PROT_INTR. Set only if Interupt is unmasked in MPU_PROT_INTR_ERRAGG_MASKWrie 0x1 to clear this Error.
  [2] MPU_PROT_ERRAGG_R5SS1_CPU0_STATUS_MPU_L2_BANK_C_PROT_ERR2 — Status of Error from MPU_PROT_INTR. Set only if Interupt is unmasked in MPU_PROT_INTR_ERRAGG_MASKWrie 0x1 to clear this Error.
  [1] MPU_PROT_ERRAGG_R5SS1_CPU0_STATUS_MPU_L2_BANK_B_PROT_ERR2 — Status of Error from MPU_PROT_INTR. Set only if Interupt is unmasked in MPU_PROT_INTR_ERRAGG_MASKWrie 0x1 to clear this Error.
  [0] MPU_PROT_ERRAGG_R5SS1_CPU0_STATUS_MPU_L2_BANK_A_PROT_ERR2 — Status of Error from MPU_PROT_INTR. Set only if Interupt is unmasked in MPU_PROT_INTR_ERRAGG_MASKWrie 0x1 to clear this Error.
0xC038 MSS_CTRL_MPU_PROT_ERRAGG_R5SS1_CORE0_STATUS_RAW
  [22] MPU_PROT_ERRAGG_R5SS1_CPU0_STATUS_RAW_MPU_L2_BANK_F_PROT_ERR2 — Raw Status of Error from MPU_PROT_INTR. Set irrespective if the Interupt is masked or unmasked in MPU_PROT_INTR_ERRAGG_MASK
  [21] MPU_PROT_ERRAGG_R5SS1_CPU0_STATUS_RAW_MPU_L2_BANK_E_PROT_ERR2 — Raw Status of Error from MPU_PROT_INTR. Set irrespective if the Interupt is masked or unmasked in MPU_PROT_INTR_ERRAGG_MASK
  [20] MPU_PROT_ERRAGG_R5SS1_CPU0_STATUS_RAW_MPU_R5SS1_PROT_ERR2 — Raw Status of Error from MPU_PROT_INTR. Set irrespective if the Interupt is masked or unmasked in MPU_PROT_INTR_ERRAGG_MASK
  [19] MPU_PROT_ERRAGG_R5SS1_CPU0_STATUS_RAW_MPU_R5SS0_PROT_ERR2 — Raw Status of Error from MPU_PROT_INTR. Set irrespective if the Interupt is masked or unmasked in MPU_PROT_INTR_ERRAGG_MASK
  [18] MPU_PROT_ERRAGG_R5SS1_CPU0_STATUS_RAW_MPU_OPTI_FLASH_PROT_ERR2 — Raw Status of Error from MPU_PROT_INTR. Set irrespective if the Interupt is masked or unmasked in MPU_PROT_INTR_ERRAGG_MASK
  [17] MPU_PROT_ERRAGG_R5SS1_CPU0_STATUS_RAW_MPU_HSM_PROT_ERR2 — Raw Status of Error from MPU_PROT_INTR. Set irrespective if the Interupt is masked or unmasked in MPU_PROT_INTR_ERRAGG_MASK
  [16] MPU_PROT_ERRAGG_R5SS1_CPU0_STATUS_RAW_MPU_CR5B1_AHB_PROT_ERR2 — Raw Status of Error from MPU_PROT_INTR. Set irrespective if the Interupt is masked or unmasked in MPU_PROT_INTR_ERRAGG_MASK
  [15] MPU_PROT_ERRAGG_R5SS1_CPU0_STATUS_RAW_MPU_CR5A1_AHB_PROT_ERR2 — Raw Status of Error from MPU_PROT_INTR. Set irrespective if the Interupt is masked or unmasked in MPU_PROT_INTR_ERRAGG_MASK
  [14] MPU_PROT_ERRAGG_R5SS1_CPU0_STATUS_RAW_MPU_CR5B0_AHB_PROT_ERR2 — Raw Status of Error from MPU_PROT_INTR. Set irrespective if the Interupt is masked or unmasked in MPU_PROT_INTR_ERRAGG_MASK
  [13] MPU_PROT_ERRAGG_R5SS1_CPU0_STATUS_RAW_MPU_CR5A0_AHB_PROT_ERR2 — Raw Status of Error from MPU_PROT_INTR. Set irrespective if the Interupt is masked or unmasked in MPU_PROT_INTR_ERRAGG_MASK
  [12] MPU_PROT_ERRAGG_R5SS1_CPU0_STATUS_RAW_MPU_SCRM2SCRP1_PROT_ERR2 — Raw Status of Error from MPU_PROT_INTR. Set irrespective if the Interupt is masked or unmasked in MPU_PROT_INTR_ERRAGG_MASK
  [11] MPU_PROT_ERRAGG_R5SS1_CPU0_STATUS_RAW_MPU_SCRM2SCRP0_PROT_ERR2 — Raw Status of Error from MPU_PROT_INTR. Set irrespective if the Interupt is masked or unmasked in MPU_PROT_INTR_ERRAGG_MASK
  [10] MPU_PROT_ERRAGG_R5SS1_CPU0_STATUS_RAW_MPU_OSPI_PROT_ERR2 — Raw Status of Error from MPU_PROT_INTR. Set irrespective if the Interupt is masked or unmasked in MPU_PROT_INTR_ERRAGG_MASK
  [9] MPU_PROT_ERRAGG_R5SS1_CPU0_STATUS_RAW_MPU_MBOX_PROT_ERR2 — Raw Status of Error from MPU_PROT_INTR. Set irrespective if the Interupt is masked or unmasked in MPU_PROT_INTR_ERRAGG_MASK
  [8] MPU_PROT_ERRAGG_R5SS1_CPU0_STATUS_RAW_MPU_DTHE_A_PROT_ERR2 — Raw Status of Error from MPU_PROT_INTR. Set irrespective if the Interupt is masked or unmasked in MPU_PROT_INTR_ERRAGG_MASK
  [7] MPU_PROT_ERRAGG_R5SS1_CPU0_STATUS_RAW_MPU_CR5B1_AXIS_PROT_ERR2 — Raw Status of Error from MPU_PROT_INTR. Set irrespective if the Interupt is masked or unmasked in MPU_PROT_INTR_ERRAGG_MASK
  [6] MPU_PROT_ERRAGG_R5SS1_CPU0_STATUS_RAW_MPU_CR5A1_AXIS_PROT_ERR2 — Raw Status of Error from MPU_PROT_INTR. Set irrespective if the Interupt is masked or unmasked in MPU_PROT_INTR_ERRAGG_MASK
  [5] MPU_PROT_ERRAGG_R5SS1_CPU0_STATUS_RAW_MPU_CR5B0_AXIS_PROT_ERR2 — Raw Status of Error from MPU_PROT_INTR. Set irrespective if the Interupt is masked or unmasked in MPU_PROT_INTR_ERRAGG_MASK
  [4] MPU_PROT_ERRAGG_R5SS1_CPU0_STATUS_RAW_MPU_CR5A0_AXIS_PROT_ERR2 — Raw Status of Error from MPU_PROT_INTR. Set irrespective if the Interupt is masked or unmasked in MPU_PROT_INTR_ERRAGG_MASK
  [3] MPU_PROT_ERRAGG_R5SS1_CPU0_STATUS_RAW_MPU_L2_BANK_D_PROT_ERR2 — Raw Status of Error from MPU_PROT_INTR. Set irrespective if the Interupt is masked or unmasked in MPU_PROT_INTR_ERRAGG_MASK
  [2] MPU_PROT_ERRAGG_R5SS1_CPU0_STATUS_RAW_MPU_L2_BANK_C_PROT_ERR2 — Raw Status of Error from MPU_PROT_INTR. Set irrespective if the Interupt is masked or unmasked in MPU_PROT_INTR_ERRAGG_MASK
  [1] MPU_PROT_ERRAGG_R5SS1_CPU0_STATUS_RAW_MPU_L2_BANK_B_PROT_ERR2 — Raw Status of Error from MPU_PROT_INTR. Set irrespective if the Interupt is masked or unmasked in MPU_PROT_INTR_ERRAGG_MASK
  [0] MPU_PROT_ERRAGG_R5SS1_CPU0_STATUS_RAW_MPU_L2_BANK_A_PROT_ERR2 — Raw Status of Error from MPU_PROT_INTR. Set irrespective if the Interupt is masked or unmasked in MPU_PROT_INTR_ERRAGG_MASK
0x10000 MSS_CTRL_R5SS1_CORE1_MBOX_WRITE_DONE
  [4n] R5SS1_CORE1_MBOX_WRITE_DONE_PROC_{n} (n=0..7) — Write pulse bit field:This register should be written once finishing Writing into the mailbox memory of processor {n}
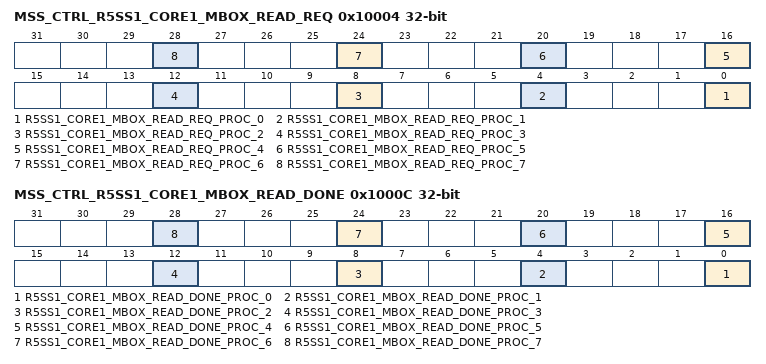
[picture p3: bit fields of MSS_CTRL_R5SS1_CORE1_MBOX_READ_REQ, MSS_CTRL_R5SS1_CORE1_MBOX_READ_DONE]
0x10004 MSS_CTRL_R5SS1_CORE1_MBOX_READ_REQ
  [4n] R5SS1_CORE1_MBOX_READ_REQ_PROC_{n} (n=0..7) — This is request from processor {n} to mss_CR5B. Requesting it to read from mailbox.
0x10008 MSS_CTRL_R5SS1_CORE1_MBOX_READ_DONE_ACK
  [7:0] R5SS1_CORE1_MBOX_READ_DONE_ACK_PROC — Write pulse bit field:For bits 0 to7:Wrting1'b1 : Generates pulse interrupt to corresponding proc from MSS_CR5
0x1000C MSS_CTRL_R5SS1_CORE1_MBOX_READ_DONE
  [4n] R5SS1_CORE1_MBOX_READ_DONE_PROC_{n} (n=0..7) — This register should be written once finishing Reading from proc{n}'s mailbox written by CR5B
0x10010 MSS_CTRL_R5SS1_CORE1_SW_INT
  [0] R5SS1_CORE1_SW_INT_PULSE — Write_pulse bit field:Writing 1'b1 to each bit will trigger MSS_SW_INT respectively to CR5A/B.
